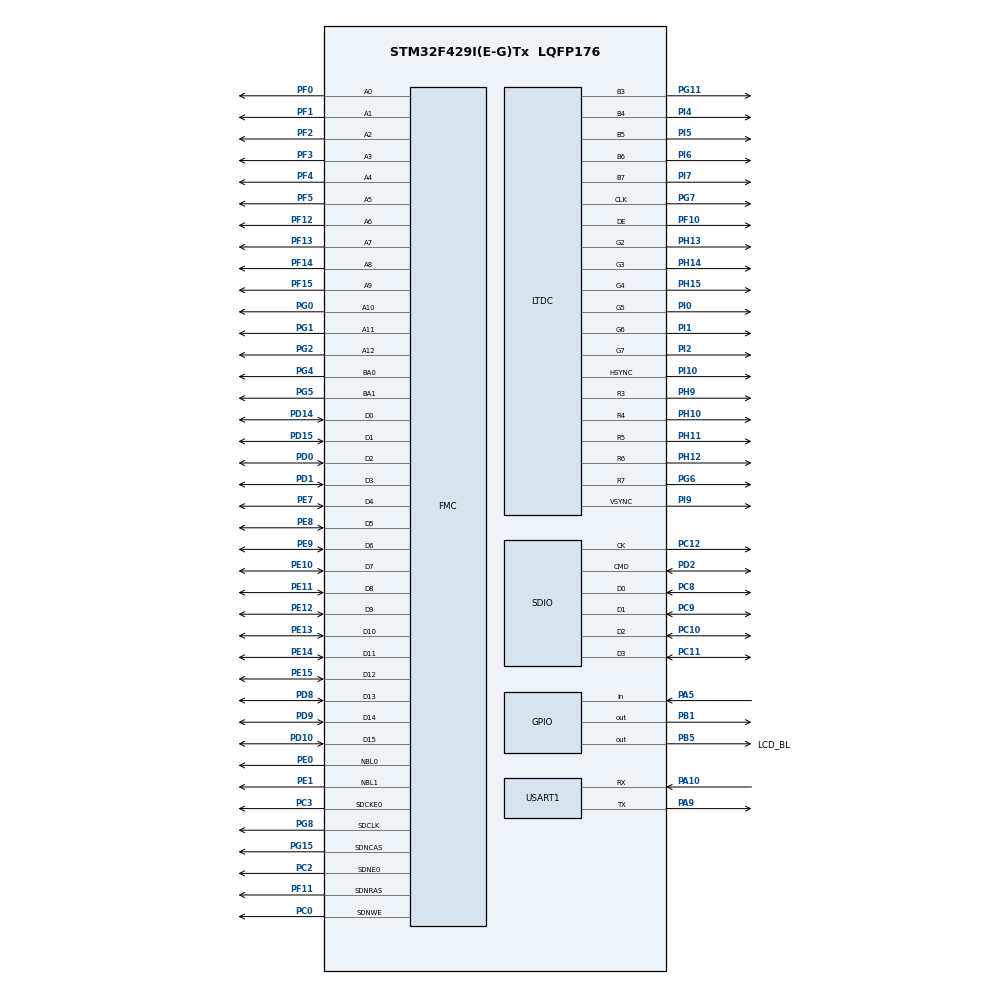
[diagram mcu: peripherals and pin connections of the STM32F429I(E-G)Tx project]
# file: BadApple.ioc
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DMA2D.AlphaModeForeground=DMA2D_NO_MODIF_ALPHA
DMA2D.ColorMode=DMA2D_OUTPUT_RGB565
DMA2D.InputAlphaForeground=0
DMA2D.Mode=DMA2D_M2M
DMA2D.OutputOffset=0
Dma.Request0=SDIO_RX
Dma.Request1=SDIO_TX
Dma.SDIO_RX.0.Direction=DMA_PERIPH_TO_MEMORY
Dma.SDIO_RX.0.FIFOMode=DMA_FIFOMODE_ENABLE
Dma.SDIO_RX.0.FIFOThreshold=DMA_FIFO_THRESHOLD_FULL
Dma.SDIO_RX.0.Instance=DMA2_Stream3
Dma.SDIO_RX.0.MemBurst=DMA_MBURST_INC4
Dma.SDIO_RX.0.MemDataAlignment=DMA_MDATAALIGN_WORD
Dma.SDIO_RX.0.MemInc=DMA_MINC_ENABLE
Dma.SDIO_RX.0.Mode=DMA_PFCTRL
Dma.SDIO_RX.0.PeriphBurst=DMA_PBURST_INC4
Dma.SDIO_RX.0.PeriphDataAlignment=DMA_PDATAALIGN_WORD
Dma.SDIO_RX.0.PeriphInc=DMA_PINC_DISABLE
Dma.SDIO_RX.0.Priority=DMA_PRIORITY_VERY_HIGH
Dma.SDIO_TX.1.Direction=DMA_MEMORY_TO_PERIPH
Dma.SDIO_TX.1.FIFOMode=DMA_FIFOMODE_ENABLE
Dma.SDIO_TX.1.FIFOThreshold=DMA_FIFO_THRESHOLD_FULL
Dma.SDIO_TX.1.Instance=DMA2_Stream6
Dma.SDIO_TX.1.MemBurst=DMA_MBURST_INC4
Dma.SDIO_TX.1.MemDataAlignment=DMA_MDATAALIGN_WORD
Dma.SDIO_TX.1.MemInc=DMA_MINC_ENABLE
Dma.SDIO_TX.1.Mode=DMA_PFCTRL
Dma.SDIO_TX.1.PeriphBurst=DMA_PBURST_INC4
Dma.SDIO_TX.1.PeriphDataAlignment=DMA_PDATAALIGN_WORD
Dma.SDIO_TX.1.PeriphInc=DMA_PINC_DISABLE
Dma.SDIO_TX.1.Priority=DMA_PRIORITY_VERY_HIGH
FATFS.BSP.number=1
FATFS._CODE_PAGE=936
FATFS._FS_EXFAT=1
FATFS._FS_LOCK=5
FATFS._USE_FORWARD=1
FATFS._USE_LFN=2
FATFS0.BSP.STBoard=false
FATFS0.BSP.api=Unknown
FATFS0.BSP.i2caddr=0
FATFS0.BSP.instance=PA5
FATFS0.BSP.ip=GPIO
FATFS0.BSP.mode=Input
FATFS0.BSP.name=Detect_SDIO
FATFS0.BSP.solution=PA5
FMC.CASLatency1=FMC_SDRAM_CAS_LATENCY_3
FMC.ColumnBitsNumber1=FMC_SDRAM_COLUMN_BITS_NUM_9
FMC.ExitSelfRefreshDelay1=8
FMC.LoadToActiveDelay1=2
FMC.RCDDelay1=2
FMC.RPDelay1=2
FMC.ReadBurst1=FMC_SDRAM_RBURST_ENABLE
FMC.ReadPipeDelay1=FMC_SDRAM_RPIPE_DELAY_1
FMC.RowCycleDelay1=6
FMC.SDClockPeriod1=FMC_SDRAM_CLOCK_PERIOD_2
FMC.SelfRefreshTime1=6
FMC.WriteProtection1=FMC_SDRAM_WRITE_PROTECTION_DISABLE
FMC.WriteRecoveryTime1=4
LTDC.ActiveH=600
LTDC.ActiveW=1024
LTDC.Alpha_L0=255
LTDC.Blue_L0=0
LTDC.FBStartAdress_L0=0xc0000000
LTDC.FBStartAdress_L1=0xc4000000
LTDC.Green_L0=0
LTDC.HBP=140
LTDC.HFP=160
LTDC.HSync=20
LTDC.ImageHeight_L0=480
LTDC.ImageHeight_L1=240
LTDC.ImageWidth_L0=640
LTDC.ImageWidth_L1=320
LTDC.Layers=0
LTDC.PixelFormat_L0=LTDC_PIXEL_FORMAT_RGB565
LTDC.PixelFormat_L1=LTDC_PIXEL_FORMAT_RGB565
LTDC.Red_L0=0
LTDC.VBP=20
LTDC.VFP=12
LTDC.VSync=3
LTDC.WindowX0_L0=190
LTDC.WindowX0_L1=703
LTDC.WindowX1_L0=829
LTDC.WindowX1_L1=1023
LTDC.WindowY0_L0=59
LTDC.WindowY0_L1=359
LTDC.WindowY1_L0=539
LTDC.WindowY1_L1=599
Mcu.Family=STM32F4
Mcu.Name=STM32F429I(E-G)Tx
Mcu.Package=LQFP176
NVIC.DMA2D_IRQn=true\:0\:1\:false\:false\:true\:true\:true
NVIC.DMA2_Stream3_IRQn=true\:0\:0\:false\:false\:true\:false\:true
NVIC.DMA2_Stream6_IRQn=true\:0\:0\:false\:false\:true\:false\:true
NVIC.LTDC_IRQn=true\:0\:2\:false\:false\:true\:true\:true
NVIC.PriorityGroup=NVIC_PRIORITYGROUP_2
PA10.Mode=Asynchronous
PA10.Signal=USART1_RX
PA13.Mode=Trace_Asynchronous_SW
PA13.Signal=SYS_JTMS-SWDIO
PA14.Mode=Trace_Asynchronous_SW
PA14.Signal=SYS_JTCK-SWCLK
PA5.Signal=GPIO_Input
PA9.Mode=Asynchronous
PA9.Signal=USART1_TX
PB1.Signal=GPIO_Output
PB3.Mode=Trace_Asynchronous_SW
PB3.Signal=SYS_JTDO-SWO
PB5.GPIO_Label=LCD_BL
PB5.Signal=GPIO_Output
PC0.GPIO_PuPd=GPIO_PULLUP
PC0.Signal=FMC_SDNWE
PC10.GPIO_PuPd=GPIO_PULLUP
PC10.Mode=SD_4_bits_Wide_bus
PC10.Signal=SDIO_D2
PC11.GPIO_PuPd=GPIO_PULLUP
PC11.Mode=SD_4_bits_Wide_bus
PC11.Signal=SDIO_D3
PC12.GPIO_PuPd=GPIO_PULLUP
PC12.Mode=SD_4_bits_Wide_bus
PC12.Signal=SDIO_CK
PC14/OSC32_IN.Mode=LSE-External-Oscillator
PC14/OSC32_IN.Signal=RCC_OSC32_IN
PC15/OSC32_OUT.Mode=LSE-External-Oscillator
PC15/OSC32_OUT.Signal=RCC_OSC32_OUT
PC2.GPIO_PuPd=GPIO_PULLUP
PC2.Mode=SdramChipSelect1_1
PC2.Signal=FMC_SDNE0
PC3.GPIO_PuPd=GPIO_PULLUP
PC3.Mode=SdramChipSelect1_1
PC3.Signal=FMC_SDCKE0
PC8.GPIO_PuPd=GPIO_PULLUP
PC8.Mode=SD_4_bits_Wide_bus
PC8.Signal=SDIO_D0
PC9.GPIO_PuPd=GPIO_PULLUP
PC9.Mode=SD_4_bits_Wide_bus
PC9.Signal=SDIO_D1
PD0.GPIO_PuPd=GPIO_PULLUP
PD0.Signal=FMC_D2_DA2
PD1.GPIO_PuPd=GPIO_PULLUP
PD1.Signal=FMC_D3_DA3
PD10.GPIO_PuPd=GPIO_PULLUP
PD10.Signal=FMC_D15_DA15
PD14.GPIO_PuPd=GPIO_PULLUP
PD14.Signal=FMC_D0_DA0
PD15.GPIO_PuPd=GPIO_PULLUP
PD15.Signal=FMC_D1_DA1
PD2.GPIO_PuPd=GPIO_PULLUP
PD2.Mode=SD_4_bits_Wide_bus
PD2.Signal=SDIO_CMD
PD8.GPIO_PuPd=GPIO_PULLUP
PD8.Signal=FMC_D13_DA13
PD9.GPIO_PuPd=GPIO_PULLUP
PD9.Signal=FMC_D14_DA14
PE0.GPIO_PuPd=GPIO_PULLUP
PE0.Signal=FMC_NBL0
PE1.GPIO_PuPd=GPIO_PULLUP
PE1.Signal=FMC_NBL1
PE10.GPIO_PuPd=GPIO_PULLUP
PE10.Signal=FMC_D7_DA7
PE11.GPIO_PuPd=GPIO_PULLUP
PE11.Signal=FMC_D8_DA8
PE12.GPIO_PuPd=GPIO_PULLUP
PE12.Signal=FMC_D9_DA9
PE13.GPIO_PuPd=GPIO_PULLUP
PE13.Signal=FMC_D10_DA10
PE14.GPIO_PuPd=GPIO_PULLUP
PE14.Signal=FMC_D11_DA11
PE15.GPIO_PuPd=GPIO_PULLUP
PE15.Signal=FMC_D12_DA12
PE7.GPIO_PuPd=GPIO_PULLUP
PE7.Signal=FMC_D4_DA4
PE8.GPIO_PuPd=GPIO_PULLUP
PE8.Signal=FMC_D5_DA5
PE9.GPIO_PuPd=GPIO_PULLUP
PE9.Signal=FMC_D6_DA6
PF0.GPIO_PuPd=GPIO_PULLUP
PF0.Signal=FMC_A0
PF1.GPIO_PuPd=GPIO_PULLUP
PF1.Signal=FMC_A1
PF10.GPIO_Speed=GPIO_SPEED_FREQ_VERY_HIGH
PF10.Mode=RGB565
PF10.Signal=LTDC_DE
PF11.GPIO_PuPd=GPIO_PULLUP
PF11.Signal=FMC_SDNRAS
PF12.GPIO_PuPd=GPIO_PULLUP
PF12.Signal=FMC_A6
PF13.GPIO_PuPd=GPIO_PULLUP
PF13.Signal=FMC_A7
PF14.GPIO_PuPd=GPIO_PULLUP
PF14.Signal=FMC_A8
PF15.GPIO_PuPd=GPIO_PULLUP
PF15.Signal=FMC_A9
PF2.GPIO_PuPd=GPIO_PULLUP
PF2.Signal=FMC_A2
PF3.GPIO_PuPd=GPIO_PULLUP
PF3.Signal=FMC_A3
PF4.GPIO_PuPd=GPIO_PULLUP
PF4.Signal=FMC_A4
PF5.GPIO_PuPd=GPIO_PULLUP
PF5.Signal=FMC_A5
PG0.GPIO_PuPd=GPIO_PULLUP
PG0.Signal=FMC_A10
PG1.GPIO_PuPd=GPIO_PULLUP
PG1.Signal=FMC_A11
PG11.GPIO_Speed=GPIO_SPEED_FREQ_VERY_HIGH
PG11.Mode=RGB565
PG11.Signal=LTDC_B3
PG15.GPIO_PuPd=GPIO_PULLUP
PG15.Signal=FMC_SDNCAS
PG2.GPIO_PuPd=GPIO_PULLUP
PG2.Signal=FMC_A12
PG4.GPIO_PuPd=GPIO_PULLUP
PG4.Signal=FMC_A14_BA0
PG5.GPIO_PuPd=GPIO_PULLUP
PG5.Signal=FMC_A15_BA1
PG6.GPIO_Speed=GPIO_SPEED_FREQ_VERY_HIGH
PG6.Mode=RGB565
PG6.Signal=LTDC_R7
PG7.GPIO_Speed=GPIO_SPEED_FREQ_VERY_HIGH
PG7.Mode=RGB565
PG7.Signal=LTDC_CLK
PG8.GPIO_PuPd=GPIO_PULLUP
PG8.Signal=FMC_SDCLK
PH0/OSC_IN.Mode=HSE-External-Oscillator
PH0/OSC_IN.Signal=RCC_OSC_IN
PH1/OSC_OUT.Mode=HSE-External-Oscillator
PH1/OSC_OUT.Signal=RCC_OSC_OUT
PH10.GPIO_Speed=GPIO_SPEED_FREQ_VERY_HIGH
PH10.Mode=RGB565
PH10.Signal=LTDC_R4
PH11.GPIO_Speed=GPIO_SPEED_FREQ_VERY_HIGH
PH11.Mode=RGB565
PH11.Signal=LTDC_R5
PH12.GPIO_Speed=GPIO_SPEED_FREQ_VERY_HIGH
PH12.Mode=RGB565
PH12.Signal=LTDC_R6
PH13.GPIO_Speed=GPIO_SPEED_FREQ_VERY_HIGH
PH13.Mode=RGB565
PH13.Signal=LTDC_G2
PH14.GPIO_Speed=GPIO_SPEED_FREQ_VERY_HIGH
PH14.Mode=RGB565
PH14.Signal=LTDC_G3
PH15.GPIO_Speed=GPIO_SPEED_FREQ_VERY_HIGH
PH15.Mode=RGB565
PH15.Signal=LTDC_G4
PH9.GPIO_Speed=GPIO_SPEED_FREQ_VERY_HIGH
PH9.Mode=RGB565
PH9.Signal=LTDC_R3
PI0.GPIO_Speed=GPIO_SPEED_FREQ_VERY_HIGH
PI0.Mode=RGB565
PI0.Signal=LTDC_G5
PI1.GPIO_Speed=GPIO_SPEED_FREQ_VERY_HIGH
PI1.Mode=RGB565
PI1.Signal=LTDC_G6
PI10.GPIO_Speed=GPIO_SPEED_FREQ_VERY_HIGH
PI10.Mode=RGB565
PI10.Signal=LTDC_HSYNC
PI2.GPIO_Speed=GPIO_SPEED_FREQ_VERY_HIGH
PI2.Mode=RGB565
PI2.Signal=LTDC_G7
PI4.GPIO_Speed=GPIO_SPEED_FREQ_VERY_HIGH
PI4.Mode=RGB565
PI4.Signal=LTDC_B4
PI5.GPIO_Speed=GPIO_SPEED_FREQ_VERY_HIGH
PI5.Mode=RGB565
PI5.Signal=LTDC_B5
PI6.GPIO_Speed=GPIO_SPEED_FREQ_VERY_HIGH
PI6.Mode=RGB565
PI6.Signal=LTDC_B6
PI7.GPIO_Speed=GPIO_SPEED_FREQ_VERY_HIGH
PI7.Mode=RGB565
PI7.Signal=LTDC_B7
PI9.GPIO_Speed=GPIO_SPEED_FREQ_VERY_HIGH
PI9.Mode=RGB565
PI9.Signal=LTDC_VSYNC
ProjectManager.HeapSize=0x2000
ProjectManager.StackSize=0x1000
ProjectManager.TargetToolchain=STM32CubeIDE
RCC.48MHZClocksFreq_Value=45000000
RCC.AHBFreq_Value=180000000
RCC.APB1CLKDivider=RCC_HCLK_DIV4
RCC.APB1Freq_Value=45000000
RCC.APB1TimFreq_Value=90000000
RCC.APB2CLKDivider=RCC_HCLK_DIV2
RCC.APB2Freq_Value=90000000
RCC.APB2TimFreq_Value=180000000
RCC.CortexFreq_Value=180000000
RCC.HCLKFreq_Value=180000000
RCC.HSE_VALUE=25000000
RCC.HSI_VALUE=16000000
RCC.PLLM=15
RCC.PLLN=216
RCC.PLLQ=8
RCC.PLLSAIN=84
RCC.PLLSourceVirtual=RCC_PLLSOURCE_HSE
RCC.SYSCLKFreq_VALUE=180000000
RCC.SYSCLKSource=RCC_SYSCLKSOURCE_PLLCLK
RCC.VCOOutputFreq_Value=360000000
SDIO.ClockDiv=0
SH.FMC_A0.0=FMC_A0,13b-sda1
SH.FMC_A1.0=FMC_A1,13b-sda1
SH.FMC_A10.0=FMC_A10,13b-sda1
SH.FMC_A11.0=FMC_A11,13b-sda1
SH.FMC_A12.0=FMC_A12,13b-sda1
SH.FMC_A14_BA0.0=FMC_BA0,FourSdramBanks1
SH.FMC_A15_BA1.0=FMC_BA1,FourSdramBanks1
SH.FMC_A2.0=FMC_A2,13b-sda1
SH.FMC_A3.0=FMC_A3,13b-sda1
SH.FMC_A4.0=FMC_A4,13b-sda1
SH.FMC_A5.0=FMC_A5,13b-sda1
SH.FMC_A6.0=FMC_A6,13b-sda1
SH.FMC_A7.0=FMC_A7,13b-sda1
SH.FMC_A8.0=FMC_A8,13b-sda1
SH.FMC_A9.0=FMC_A9,13b-sda1
SH.FMC_D0_DA0.0=FMC_D0,sd-16b-d1
SH.FMC_D10_DA10.0=FMC_D10,sd-16b-d1
SH.FMC_D11_DA11.0=FMC_D11,sd-16b-d1
SH.FMC_D12_DA12.0=FMC_D12,sd-16b-d1
SH.FMC_D13_DA13.0=FMC_D13,sd-16b-d1
SH.FMC_D14_DA14.0=FMC_D14,sd-16b-d1
SH.FMC_D15_DA15.0=FMC_D15,sd-16b-d1
SH.FMC_D1_DA1.0=FMC_D1,sd-16b-d1
SH.FMC_D2_DA2.0=FMC_D2,sd-16b-d1
SH.FMC_D3_DA3.0=FMC_D3,sd-16b-d1
SH.FMC_D4_DA4.0=FMC_D4,sd-16b-d1
SH.FMC_D5_DA5.0=FMC_D5,sd-16b-d1
SH.FMC_D6_DA6.0=FMC_D6,sd-16b-d1
SH.FMC_D7_DA7.0=FMC_D7,sd-16b-d1
SH.FMC_D8_DA8.0=FMC_D8,sd-16b-d1
SH.FMC_D9_DA9.0=FMC_D9,sd-16b-d1
SH.FMC_NBL0.0=FMC_NBL0,Sd2ByteEnable1
SH.FMC_NBL1.0=FMC_NBL1,Sd2ByteEnable1
SH.FMC_SDCLK.0=FMC_SDCLK,13b-sda1
SH.FMC_SDNCAS.0=FMC_SDNCAS,13b-sda1
SH.FMC_SDNRAS.0=FMC_SDNRAS,13b-sda1
SH.FMC_SDNWE.0=FMC_SDNWE,13b-sda1
USART1.VirtualMode=VM_ASYNC
VP_DMA2D_VS_DMA2D.Mode=DMA2D_Activate
VP_FATFS_VS_SDIO.Mode=SDIO
VP_LIBJPEG_VS_JPEGLIB.Mode=Enabled
board=custom

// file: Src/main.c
/* USER CODE BEGIN Header */
/**
 ******************************************************************************
 * @file           : main.c
 * @brief          : Main program body
 ******************************************************************************
 * @attention
 *
 * <h2><center>&copy; Copyright (c) 2019 STMicroelectronics.
 * All rights reserved.</center></h2>
 *
 * This software component is licensed by ST under BSD 3-Clause license,
 * the "License"; You may not use this file except in compliance with the
 * License. You may obtain a copy of the License at:
 *                        opensource.org/licenses/BSD-3-Clause
 *
 ******************************************************************************
 */
/* USER CODE END Header */

#include "main.h"
#include "dma.h"
#include "dma2d.h"
#include "fatfs.h"
#include "libjpeg.h"
#include "ltdc.h"
#include "sdio.h"
#include "usart.h"
#include "gpio.h"
#include "fmc.h"

/* USER CODE BEGIN Includes */

#include <stdio.h>
//#include "RGB565_240x130_1.h"
//#include "L8_320X240.h"
#include "test_pic_1.h"

/* USER CODE END Includes */

/* USER CODE BEGIN PTD */
#ifdef __GNUC__
#define PUTCHAR_PROTOTYPE int __io_putchar(int ch)
#else
#define PUTCHAR_PROTOTYPE int fputc(int ch, FILE *f)
#endif
PUTCHAR_PROTOTYPE
{
    while ((USART1->SR & 0X40) == 0);
    USART1->DR = (uint8_t) ch;
    return ch;
}

struct jpeg_decompress_struct cinfo;
/* This struct represents a JPEG error handler */
struct jpeg_error_mgr jerr;

/* USER CODE END PTD */

/* USER CODE BEGIN PD */

#define SDRAM_BANK_ADDR     ((uint32_t)0XC0000000)
#define VIDEO_WIDTH 640
#define VIDEO_HEIGHT 480

#define VIDEO_ARRAY_WIDTH 240
#define VIDEO_ARRAY_HEIGHT 180

#define IMG_WIDTH 240
#define IMG_HEIGHT 180

#define LCD_WIDTH 1024
#define LCD_HEIGHT 600

/* USER CODE END PD */

/* USER CODE BEGIN PV */
extern LTDC_HandleTypeDef hltdc;
extern DMA2D_HandleTypeDef hdma2d;

extern const uint16_t pic_array[43200];

//uint32_t aMemory[262144] __attribute__((section(".ExtRAMData")));
uint16_t aMemory0[1200 * 800] __attribute__((section(".ExtRAMData"))); // 1024 * 1024 /4    //1MB / 4
uint16_t aMemory1[1200 * 800] __attribute__((section(".ExtRAMData1"))); // 1024 * 1024 /4    //1MB / 4
uint16_t aMemory2[1200 * 800] __attribute__((section(".ExtRAMData2"))); // 1024 * 1024 /4    //1MB / 4

extern FATFS SDFatFS; /* File system object for SD logical drive */
extern FIL SDFile; /* File object for SD */
extern char SDPath[4];

char video_badApple_240x180[] = { "badapple_15_fps_240_180.bin" };
char video_badApple_640x480[] = { "badapple_15_fps.bin" };
char video_badApple_800x600[] = { "badApple_15_fps_800_600.bin" };

char video_landscape_640x480[] = { "landscape_15_fps.bin" };
char video_landscape_1024x600[] = { "landscape_15_fps_1024_600.bin" };

char jpeg_name[] = { "1024x600.jpg" };
char jpeg_color_bar[] = { "1024x600_color_bar.jpg" };

uint8_t _aucLine[4096];

uint32_t offset = 0;
uint32_t line_counter = 0;

uint8_t buf0_ready = 0;
uint8_t buf1_ready = 0;
volatile uint8_t line_start = 0;
volatile uint8_t dma_cplt = 0;

uint16_t pos[12][2] = { { 15, 14 }, { 265, 14 }, { 517, 14 }, { 769, 14 }, { 15, 209 }, { 265, 209 }, { 517, 209 }, { 769, 209 }, { 15, 404 }, { 265, 404 }, { 517, 404 }, { 769, 404 } };
uint16_t img_buf[43200] = { 0 };

uint16_t rgb565;

LTDC_ColorTypeDef lcd_back_color;
/* USER CODE END PV */

void SystemClock_Config (void);

/* USER CODE BEGIN 0 */
void DMA2D_cplt (struct __DMA2D_HandleTypeDef*hdma2d)
{
    dma_cplt = 1;
}
void HAL_LTDC_LineEventCallback (LTDC_HandleTypeDef*hltdc)
{
    __HAL_LTDC_ENABLE_IT(hltdc, LTDC_IT_LI);
    line_start = 1;
}

FRESULT scan_files (char*path) /* Start node to be scanned (also used as work area) */
{
    FRESULT res;
    FILINFO fno;
    DIR dir;
    int i;
    char *fn; /* This function is assuming non-Unicode cfg. */
    res = f_opendir (&dir, path); /* Open the directory */
    if (res == FR_OK)
    {
	i = strlen (path);
	for (;;)
	{
	    res = f_readdir (&dir, &fno); /* Read a directory item */
	    if (res != FR_OK)
	    {
		break; /* Break on error or end of dir */
	    }
	    else if (fno.fname[0] == 0)
	    {
		printf ("%s\r\n", path);
		break;
	    }
	    fn = fno.fname;
	    if (fno.fattrib & AM_DIR)
	    { /* It is a directory */
		sprintf (&path[i], "/%s", fn);
		res = scan_files (path);
		if (res != FR_OK)
		    break;
		path[i] = 0;
	    }
	    else
	    { /* It is a file. */
		printf ("%s/%s\r\n", path, fn);
	    }
	}
    }
    return res;
}

void LCD_test ()
{
    int32_t t = 0;

    for (t = 0; t < 640 * 120; t++)
    {
	aMemory0[t] = 0xf800; //RED
    }
    for (; t < 640 * 240; t++)
    {
	aMemory0[t] = 0x07E0; //Green
    }
    for (; t < 640 * 360; t++)
    {
	aMemory0[t] = 0x001F; //Blue
    }
    for (; t < 640 * 480; t++)
    {
	aMemory0[t] = 0xF81F; //R+B
    }
}

void play_video (char*video_name,uint16_t vidoe_width,uint16_t video_hight)
{
    FRESULT res;
    UINT dmy;
    FILINFO ino;

    HAL_LTDC_SetWindowSize (&hltdc, vidoe_width, video_hight, 0);
    HAL_LTDC_SetWindowPosition (&hltdc, (LCD_WIDTH - vidoe_width) / 2, (LCD_HEIGHT - video_hight) / 2, 0);
    HAL_LTDC_ProgramLineEvent (&hltdc, 0);

    res = f_open (&SDFile, video_name, FA_READ);

    f_stat (video_name, &ino);

    hdma2d.XferCpltCallback = DMA2D_cplt;
    uint32_t t1 = 0;
    uint32_t t2 = 0;

    while (res == FR_OK && SDFile.fptr < ino.fsize)
    {
	HAL_GPIO_TogglePin (GPIOB, GPIO_PIN_1);
	t1 = HAL_GetTick ();
	res = f_read (&SDFile, aMemory1, vidoe_width * video_hight * 2, &dmy);

	t2 = HAL_GetTick ();
	printf ("F_read: %d \r\n", t2 - t1);

	while (line_start != 1);

	t1 = HAL_GetTick ();
	printf ("line_start: %d \r\n", t1 - t2);

	if (HAL_DMA2D_Start_IT (&hdma2d, aMemory1, aMemory0, vidoe_width, video_hight) != HAL_OK)
	{
	    Error_Handler ();
	}
	while (dma_cplt != 1);
	t2 = HAL_GetTick ();
	printf ("DMA: %d \r\n", t2 - t1);

	dma_cplt = 0;
	line_start = 0;
    }
    f_close (&SDFile);
}
void pic_Array_test ()
{
    HAL_LTDC_SetWindowSize (&hltdc, 1024, 600, 0);
    HAL_LTDC_SetWindowPosition (&hltdc, 0, 0, 0);

    uint32_t pos_x = 0;
    uint32_t pos_y = 0;
    uint32_t pix = 0;
    uint32_t a1 = 0;
    uint32_t a2 = 0;
    uint32_t a3 = 0;
    uint8_t pos_num = 0;
    int p = 0;

    for (p = 0; p < 1024 * 600; p++)
    {
	aMemory0[p] = 0x00; // black
    }
    p = 0;
    for (; p < 240 * 45; p++)
    {
	img_buf[p] = 0xf800; // red
    }
    for (; p < 240 * 90; p++)
    {
	img_buf[p] = 0x07E0; // green
    }
    for (p; p < 240 * 135; p++)
    {
	img_buf[p] = 0x001F; // blue
    }
    for (; p < 240 * 180; p++)
    {
	img_buf[p] = 0xF81F; // purple
    }

    while (pix++ < 43200)
    {
	pos_x = pix % IMG_WIDTH;
	pos_y = pix / IMG_WIDTH;

	for (pos_num = 0; pos_num < 12; pos_num++)
	{
	    a1 = pos[pos_num][0] + pos_x;
	    a2 = 1024 * pos[pos_num][1] + 1024 * pos_y;
	    a3 = a1 + a2;
	    aMemory0[a3] = img_buf[pix];
	}
    }
}

void video_Array (char*vidoe_array_name)
{
    FRESULT res;
    UINT dmy;
    FILINFO ino;

    uint32_t pos_x = 0;
    uint32_t pos_y = 0;
    uint32_t pix = 0;
    uint32_t a1 = 0;
    uint32_t a2 = 0;
    uint32_t a3 = 0;
    uint8_t pos_num = 0;

    for (int p = 0; p < 1024 * 600; p++)
    {
	aMemory1[p] = 0b1111100000000000;
    }

    res = f_open (&SDFile, vidoe_array_name, FA_READ);

    f_stat (vidoe_array_name, &ino);

    hdma2d.XferCpltCallback = DMA2D_cplt;
    HAL_LTDC_ProgramLineEvent (&hltdc, 0);
    HAL_LTDC_SetWindowSize (&hltdc, 1024, 600, 0);
    HAL_LTDC_SetWindowPosition (&hltdc, 0, 0, 0);
    dma_cplt = 1;
    while (res == FR_OK && SDFile.fptr < ino.fsize)
    {
	HAL_GPIO_TogglePin (GPIOB, GPIO_PIN_1);
	f_read (&SDFile, img_buf, VIDEO_ARRAY_WIDTH * VIDEO_ARRAY_HEIGHT * 2, &dmy);
	pix = 0;
	while (pix++ < 43200)
	{
	    pos_x = pix % IMG_WIDTH;
	    pos_y = pix / IMG_WIDTH;

	    for (pos_num = 0; pos_num < 12; pos_num++)
	    {
		a1 = pos[pos_num][0] + pos_x;
		a2 = 1024 * pos[pos_num][1] + 1024 * pos_y;
		a3 = a1 + a2;
		aMemory1[a3] = img_buf[pix];
	    }
	}

	while (line_start != 1);

	while (dma_cplt != 1);

	if (HAL_DMA2D_Start_IT (&hdma2d, aMemory1, aMemory0, 1024, 600) != HAL_OK)
	{
	    Error_Handler ();
	}
	dma_cplt = 0;
	line_start = 0;
    }
    f_close (&SDFile);
}

void jpeg_decode (JFILE*file,uint32_t width,uint8_t*buff,uint8_t (*callback) (uint8_t*,uint32_t))
{

    /* Decode JPEG Image */
    JSAMPROW buffer[2] = { 0 }; /* Output row buffer */
    uint32_t row_stride = 0; /* physical row width in image buffer */

    buffer[0] = buff;

    /* Step 1: allocate and initialize JPEG decompression object */
    cinfo.err = jpeg_std_error (&jerr);

    /* Initialize the JPEG decompression object */
    jpeg_create_decompress(&cinfo);

    jpeg_stdio_src (&cinfo, file);

    /* Step 3: read image parameters with jpeg_read_header() */
    jpeg_read_header (&cinfo, TRUE);

    /* Step 4: set parameters for decompression */
    cinfo.dct_method = JDCT_FLOAT;

    /* Step 5: start decompressor */
    jpeg_start_decompress (&cinfo);

    row_stride = width * 3;
    while (cinfo.output_scanline < cinfo.output_height)
    {
	(void) jpeg_read_scanlines (&cinfo, buffer, 1);

	if (callback (buffer[0], cinfo.output_width) != 0)
	{
	    break;
	}
    }
    /* Step 6: Finish decompression */
    jpeg_finish_decompress (&cinfo);
    /* Step 7: Release JPEG decompression object */
    jpeg_destroy_decompress (&cinfo);

}

static uint8_t Jpeg_CallbackFunction (uint8_t*Row,uint32_t DataLength)
{
    for (uint32_t x = 0; x < DataLength; x++)
    {
	rgb565 = (((*Row) << 8) & 0xF800) | (((*(Row + 1)) << 3) & 0x07E0) | (((*(Row + 2)) >> 3) & 0x001F);
	aMemory0[1024 * line_counter + x] = rgb565;
	Row += 3;

    }
    line_counter++;
    return 0;
}
void show_jpeg (char*jpeg_name,uint16_t jpeg_width,uint16_t jpeg_hight)
{
    HAL_LTDC_SetWindowSize (&hltdc, 1024, 600, 0);
    HAL_LTDC_SetWindowPosition (&hltdc, 0, 0, 0);
    line_counter = 0;

    if (f_open (&SDFile, jpeg_name, FA_READ) == FR_OK)
    {

	jpeg_decode (&SDFile, jpeg_width, _aucLine, Jpeg_CallbackFunction);
	f_close (&SDFile);

    }
}

/* USER CODE END 0 */

int main (void)
{

    /* MCU Configuration--------------------------------------------------------*/

    /* Reset of all peripherals, Initializes the Flash interface and the Systick. */
    HAL_Init ();

    /* Configure the system clock */
    SystemClock_Config ();

    /* Initialize all configured peripherals */
    MX_GPIO_Init ();
    MX_DMA_Init ();
    MX_FMC_Init ();
    MX_LTDC_Init ();
    MX_DMA2D_Init ();
    MX_SDIO_SD_Init ();
    MX_FATFS_Init ();
    MX_USART1_UART_Init ();
    MX_LIBJPEG_Init ();
    /* USER CODE BEGIN 2 */
    SDRAM_Init ();
    LCD_test ();
    HAL_Delay (1000);

    printf ("Start\r\n");
    /*##-2- Register the file system object to the FatFs module ##############*/
    printf ("#2  %d\r\n", HAL_GetTick ());
    if (f_mount (&SDFatFS, (TCHAR const*) SDPath, 0) != FR_OK)
    {
	/* FatFs Initialization Error */
	Error_Handler ();
    }
    else
    {
//	scan_files (SDPath);
//	pic_Array_test ();
//	HAL_Delay (1000);
//	play_video (video_badApple_240x180, 240, 180);		//12FPS
//	play_video (video_landscape_640x480, 640, 480);		//12FPS
//	play_video (video_badApple_640x480, 640, 480);		//12FPS
//	play_video (video_badApple_800x600, 800, 600);		//8FPS
//	play_video (video_landscape_1024x600, 1024, 600);	//6.2FPS
//	video_Array (video_badApple_240x180);

	while (1)
	{
	    show_jpeg (jpeg_color_bar, 1024, 600);
	    HAL_Delay (1000);
	    show_jpeg (jpeg_name, 1024, 600);
	    HAL_Delay (1000);
	}

    }
    /* USER CODE END 2 */

    /* Infinite loop */
    /* USER CODE BEGIN WHILE */
    while (1)
    {
	printf ("hello\r\n");
	HAL_Delay (1000);
	/* USER CODE END WHILE */

    }
}

void SystemClock_Config (void)
{
    RCC_OscInitTypeDef RCC_OscInitStruct = { 0 };
    RCC_ClkInitTypeDef RCC_ClkInitStruct = { 0 };
    RCC_PeriphCLKInitTypeDef PeriphClkInitStruct = { 0 };

    /** Configure the main internal regulator output voltage
     */
    __HAL_RCC_PWR_CLK_ENABLE();
    __HAL_PWR_VOLTAGESCALING_CONFIG(PWR_REGULATOR_VOLTAGE_SCALE1);
    /** Initializes the CPU, AHB and APB busses clocks
     */
    RCC_OscInitStruct.OscillatorType = RCC_OSCILLATORTYPE_HSE;
    RCC_OscInitStruct.HSEState = RCC_HSE_ON;
    RCC_OscInitStruct.PLL.PLLState = RCC_PLL_ON;
    RCC_OscInitStruct.PLL.PLLSource = RCC_PLLSOURCE_HSE;
    RCC_OscInitStruct.PLL.PLLM = 15;
    RCC_OscInitStruct.PLL.PLLN = 216;
    RCC_OscInitStruct.PLL.PLLP = RCC_PLLP_DIV2;
    RCC_OscInitStruct.PLL.PLLQ = 8;
    if (HAL_RCC_OscConfig (&RCC_OscInitStruct) != HAL_OK)
    {
	Error_Handler ();
    }
    /** Activate the Over-Drive mode
     */
    if (HAL_PWREx_EnableOverDrive () != HAL_OK)
    {
	Error_Handler ();
    }
    /** Initializes the CPU, AHB and APB busses clocks
     */
    RCC_ClkInitStruct.ClockType = RCC_CLOCKTYPE_HCLK | RCC_CLOCKTYPE_SYSCLK | RCC_CLOCKTYPE_PCLK1 | RCC_CLOCKTYPE_PCLK2;
    RCC_ClkInitStruct.SYSCLKSource = RCC_SYSCLKSOURCE_PLLCLK;
    RCC_ClkInitStruct.AHBCLKDivider = RCC_SYSCLK_DIV1;
    RCC_ClkInitStruct.APB1CLKDivider = RCC_HCLK_DIV4;
    RCC_ClkInitStruct.APB2CLKDivider = RCC_HCLK_DIV2;

    if (HAL_RCC_ClockConfig (&RCC_ClkInitStruct, FLASH_LATENCY_5) != HAL_OK)
    {
	Error_Handler ();
    }
    PeriphClkInitStruct.PeriphClockSelection = RCC_PERIPHCLK_LTDC;
    PeriphClkInitStruct.PLLSAI.PLLSAIN = 84;
    PeriphClkInitStruct.PLLSAI.PLLSAIR = 2;
    PeriphClkInitStruct.PLLSAIDivR = RCC_PLLSAIDIVR_2;
    if (HAL_RCCEx_PeriphCLKConfig (&PeriphClkInitStruct) != HAL_OK)
    {
	Error_Handler ();
    }
}

void Error_Handler (void)
{
    /* USER CODE BEGIN Error_Handler_Debug */
    /* User can add his own implementation to report the HAL error return state */
    printf ("Error\r\n");
    /* USER CODE END Error_Handler_Debug */
}

/************************ (C) COPYRIGHT STMicroelectronics *****END OF FILE****/
